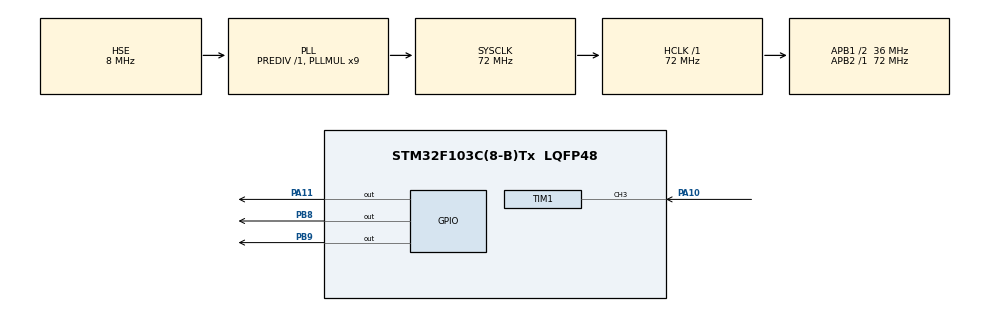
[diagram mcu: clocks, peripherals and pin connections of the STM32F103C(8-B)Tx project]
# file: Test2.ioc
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Mcu.Family=STM32F1
Mcu.Name=STM32F103C(8-B)Tx
Mcu.Package=LQFP48
NVIC.PriorityGroup=NVIC_PRIORITYGROUP_4
NVIC.TIM1_CC_IRQn=true\:0\:0\:false\:false\:true\:true\:true\:true
PA10.GPIO_Mode=GPIO_MODE_INPUT
PA10.GPIO_PuPd=GPIO_NOPULL
PA10.Signal=S_TIM1_CH3
PA11.GPIO_ModeDefaultOutputPP=GPIO_MODE_OUTPUT_PP
PA11.GPIO_PuPd=GPIO_NOPULL
PA11.Signal=GPIO_Output
PA13.Mode=Serial_Wire
PA13.Signal=SYS_JTMS-SWDIO
PA14.Mode=Serial_Wire
PA14.Signal=SYS_JTCK-SWCLK
PB8.GPIO_ModeDefaultOutputPP=GPIO_MODE_OUTPUT_OD
PB8.GPIO_PuPd=GPIO_NOPULL
PB8.Signal=GPIO_Output
PB9.GPIO_ModeDefaultOutputPP=GPIO_MODE_OUTPUT_OD
PB9.GPIO_PuPd=GPIO_NOPULL
PB9.Signal=GPIO_Output
PD0-OSC_IN.Mode=HSE-External-Oscillator
PD0-OSC_IN.Signal=RCC_OSC_IN
PD1-OSC_OUT.Mode=HSE-External-Oscillator
PD1-OSC_OUT.Signal=RCC_OSC_OUT
ProjectManager.HeapSize=0x200
ProjectManager.StackSize=0x400
ProjectManager.TargetToolchain=CMake
RCC.AHBFreq_Value=72000000
RCC.APB1CLKDivider=RCC_HCLK_DIV2
RCC.APB1Freq_Value=36000000
RCC.APB1TimFreq_Value=72000000
RCC.APB2Freq_Value=72000000
RCC.APB2TimFreq_Value=72000000
RCC.HCLKFreq_Value=72000000
RCC.PLLMUL=RCC_PLL_MUL9
RCC.PLLSourceVirtual=RCC_PLLSOURCE_HSE
RCC.SYSCLKFreq_VALUE=72000000
RCC.SYSCLKSource=RCC_SYSCLKSOURCE_PLLCLK
RCC.USBFreq_Value=72000000
SH.S_TIM1_CH3.0=TIM1_CH3,Input_Capture3_from_TI3
TIM1.AutoReloadPreload=TIM_AUTORELOAD_PRELOAD_ENABLE
TIM1.Channel-Input_Capture3_from_TI3=TIM_CHANNEL_3
TIM1.Channel-Input_Capture4_from_TI3_63=TIM_CHANNEL_4
TIM1.ICPolarity_CH4=TIM_INPUTCHANNELPOLARITY_FALLING
TIM1.Prescaler=72 - 1
VP_TIM1_VS_ClockSourceINT.Mode=Internal
VP_TIM1_VS_indirect_ch3.Mode=Input_Capture4_from_TI3_63
board=custom

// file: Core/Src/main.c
/* USER CODE BEGIN Header */
/**
  ******************************************************************************
  * @file           : main.c
  * @brief          : Main program body
  ******************************************************************************
  * @attention
  *
  * Copyright (c) 2026 STMicroelectronics.
  * All rights reserved.
  *
  * This software is licensed under terms that can be found in the LICENSE file
  * in the root directory of this software component.
  * If no LICENSE file comes with this software, it is provided AS-IS.
  *
  ******************************************************************************
  */
/* USER CODE END Header */
#include "main.h"
#include "tim.h"
#include "gpio.h"
#include "OLED.h"

void SystemClock_Config(void);

uint32_t UpEdge = 0;
uint32_t DownEdge = 0;
float Distance = 0;
uint8_t capture_complete_flag = 0;

void HAL_TIM_IC_CaptureCallback(TIM_HandleTypeDef *htim) {
  OLED_ShowString(1,1,"CB:123");  // 回调触发标记

  if (htim->Instance == TIM1) {
    // 1. 捕获CH3（上升沿）
    if (htim->Channel == TIM_CHANNEL_3) {
      UpEdge = HAL_TIM_ReadCapturedValue(htim, TIM_CHANNEL_3);
      __HAL_TIM_CLEAR_FLAG(htim,TIM_FLAG_CC3);
      __HAL_TIM_CLEAR_IT(htim,TIM_IT_CC3);
    }
    // 2. 捕获CH4（下降沿）
    if (htim->Channel == TIM_CHANNEL_4) {
      DownEdge = HAL_TIM_ReadCapturedValue(htim, TIM_CHANNEL_4);
      __HAL_TIM_CLEAR_FLAG(htim,TIM_FLAG_CC4);
      __HAL_TIM_CLEAR_IT(htim,TIM_IT_CC4);
      capture_complete_flag = 1;
    }

    // 3. 计算距离（保留逻辑）
    if (capture_complete_flag == 1) {
      uint32_t pulse_width = (DownEdge >= UpEdge) ? (DownEdge - UpEdge) : (65535 - UpEdge + DownEdge);
      Distance = pulse_width * 0.034f / 2.0f;
      capture_complete_flag = 0;
    }
  }

  // 4. 显示原始捕获值（重点！看是否变化）
  OLED_ShowString(3,1,"Up:");
  OLED_ShowNum(3,4, UpEdge, 4);        // 显示上升沿计数值
  OLED_ShowString(4,1,"Down:");
  OLED_ShowNum(4,4, DownEdge, 4);      // 显示下降沿计数值
  OLED_ShowNum(2,1,(uint32_t)Distance,3);
  OLED_ShowString(2,4,".");
  OLED_ShowNum(2,5,(uint32_t)(Distance*10)%10,1);

  OLED_Clear();
}

int main(void)
{

  /* MCU Configuration--------------------------------------------------------*/

  /* Reset of all peripherals, Initializes the Flash interface and the Systick. */
  HAL_Init();

  /* Configure the system clock */
  SystemClock_Config();

  /* Initialize all configured peripherals */
  MX_GPIO_Init();
  MX_TIM1_Init();
  HAL_Delay(20);
  OLED_Init();
  /* USER CODE BEGIN 2 */
  // 主要是为了防止异常
  __HAL_TIM_CLEAR_FLAG(&htim1, TIM_FLAG_CC3);  // 清除CH3捕获标志
  __HAL_TIM_CLEAR_IT(&htim1, TIM_IT_CC3);      // 清除CH3中断挂起位
  __HAL_TIM_CLEAR_FLAG(&htim1, TIM_FLAG_CC4);  // 清除CH4捕获标志
  __HAL_TIM_CLEAR_IT(&htim1, TIM_IT_CC4);      // 清除CH4中断挂起位

  // 2 启动TIM1的基础计数（MX_TIM1_Init仅初始化，未启动计数，必须手动启动）
  HAL_TIM_Base_Start(&htim1);

  // 3 开启CH3（Echo）和CH4（间接捕获）的「带中断」输入捕获（核心！）
  // CH3：直接捕获Echo的上升沿，开启中断
  HAL_TIM_IC_Start_IT(&htim1, TIM_CHANNEL_3);
  // CH4：间接捕获Echo的下降沿，开启中断
  HAL_TIM_IC_Start_IT(&htim1, TIM_CHANNEL_4);
  /* USER CODE END 2 */
  OLED_ShowString(1,1,"Distance:");
  /* Infinite loop */
  while (1)
  {
    // 1. 触发前清零TIM1计数器，保证每次测距的计数基准从0开始（核心！）
    __HAL_TIM_SET_COUNTER(&htim1, 0);
    HAL_GPIO_WritePin(GPIOA, GPIO_PIN_11, GPIO_PIN_SET);
    HAL_Delay(1);
    HAL_GPIO_WritePin(GPIOA, GPIO_PIN_11, GPIO_PIN_RESET);
    HAL_Delay(2);
  }
}

void SystemClock_Config(void)
{
  RCC_OscInitTypeDef RCC_OscInitStruct = {0};
  RCC_ClkInitTypeDef RCC_ClkInitStruct = {0};

  /** Initializes the RCC Oscillators according to the specified parameters
  * in the RCC_OscInitTypeDef structure.
  */
  RCC_OscInitStruct.OscillatorType = RCC_OSCILLATORTYPE_HSE;
  RCC_OscInitStruct.HSEState = RCC_HSE_ON;
  RCC_OscInitStruct.HSEPredivValue = RCC_HSE_PREDIV_DIV1;
  RCC_OscInitStruct.HSIState = RCC_HSI_ON;
  RCC_OscInitStruct.PLL.PLLState = RCC_PLL_ON;
  RCC_OscInitStruct.PLL.PLLSource = RCC_PLLSOURCE_HSE;
  RCC_OscInitStruct.PLL.PLLMUL = RCC_PLL_MUL9;
  if (HAL_RCC_OscConfig(&RCC_OscInitStruct) != HAL_OK)
  {
    Error_Handler();
  }

  /** Initializes the CPU, AHB and APB buses clocks
  */
  RCC_ClkInitStruct.ClockType = RCC_CLOCKTYPE_HCLK|RCC_CLOCKTYPE_SYSCLK
                              |RCC_CLOCKTYPE_PCLK1|RCC_CLOCKTYPE_PCLK2;
  RCC_ClkInitStruct.SYSCLKSource = RCC_SYSCLKSOURCE_PLLCLK;
  RCC_ClkInitStruct.AHBCLKDivider = RCC_SYSCLK_DIV1;
  RCC_ClkInitStruct.APB1CLKDivider = RCC_HCLK_DIV2;
  RCC_ClkInitStruct.APB2CLKDivider = RCC_HCLK_DIV1;

  if (HAL_RCC_ClockConfig(&RCC_ClkInitStruct, FLASH_LATENCY_2) != HAL_OK)
  {
    Error_Handler();
  }
}

void Error_Handler(void)
{
  __disable_irq();
  while (1)
  {
  }
}
